# GD32VW553x register map
Vendor: GigaDevice; File version: 1.0
CPU: OTHER r0p0, little endian, no MPU, no FPU, 4 interrupt priority bits
Registers are 32-bit, read-write, reset 0x0 unless marked. A register's access mark holds for its fields unless they carry their own. Offsets are from the block's base; [hi:lo] are bit positions.

## USART0 — Universal synchronous/asynchronous receiver /transmitter
Base 0x40004800
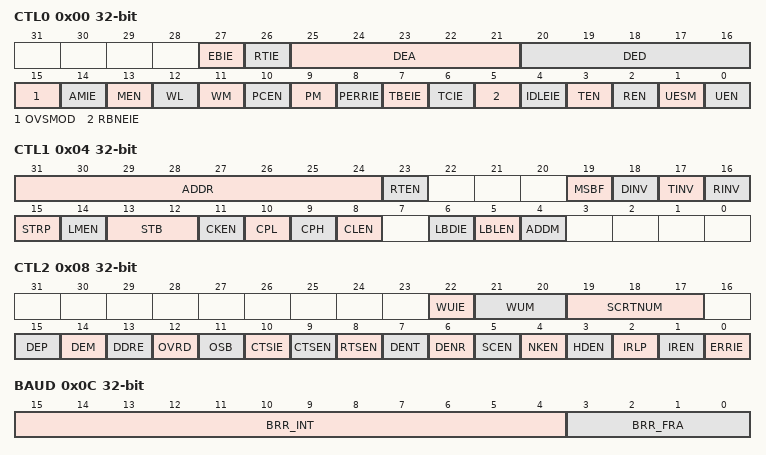
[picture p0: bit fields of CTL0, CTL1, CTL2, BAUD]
0x00 CTL0 — Control register 0
  [27] EBIE — End of Block interrupt enable
  [26] RTIE — Receiver timeout interrupt enable
  [25:21] DEA — Driver enable assertion time
  [20:16] DED — Driver enable de-assertion time
  [15] OVSMOD — Oversample mode
  [14] AMIE — ADDR match interrupt enable
  [13] MEN — Mute mode enable
  [12] WL — Word length
  [11] WM — Wakeup method in mute mode
  [10] PCEN — Parity control enable
  [9] PM — Parity mode
  [8] PERRIE — Parity error interrupt enable
  [7] TBEIE — Transmitter register empty interrupt enable
  [6] TCIE — Transmission complete interrupt enable
  [5] RBNEIE — Read data buffer not empty interrupt and overrun error interrupt enable
  [4] IDLEIE — IDLE line detected interrupt enable
  [3] TEN — Transmitter enable
  [2] REN — Receiver enable
  [1] UESM — USART enable in Deep-sleep mode
  [0] UEN — USART enable
0x04 CTL1 — Control register 1
  [31:24] ADDR — Address of the USART terminal
  [23] RTEN — Receiver timeout enable
  [19] MSBF — Most significant bit first
  [18] DINV — Data bit level inversion
  [17] TINV — TX pin level inversion
  [16] RINV — RX pin level inversion
  [15] STRP — Swap TX/RX pins
  [14] LMEN — LIN mode enable
  [13:12] STB — STOP bits length
  [11] CKEN — CK pin enable
  [10] CPL — Clock polarity
  [9] CPH — Clock phase
  [8] CLEN — CK length
  [6] LBDIE — LIN break detection interrupt enable
  [5] LBLEN — LIN break frame length
  [4] ADDM — Address detection mode
0x08 CTL2 — Control register 2
  [22] WUIE — Wakeup from deep-sleep mode interrupt enable
  [21:20] WUM — Wakeup mode from deep-sleep mode
  [19:17] SCRTNUM — Smartcard auto-retry number
  [15] DEP — Driver enable polarity mode
  [14] DEM — Driver enable mode
  [13] DDRE — Disable DMA on reception error
  [12] OVRD — Overrun disable
  [11] OSB — One sample bit method
  [10] CTSIE — CTS interrupt enable
  [9] CTSEN — CTS enable
  [8] RTSEN — RTS enable
  [7] DENT — DMA enable for transmission
  [6] DENR — DMA enable for reception
  [5] SCEN — Smartcard mode enable
  [4] NKEN — NACK enable in Smartcard mode
  [3] HDEN — Half-duplex enable
  [2] IRLP — IrDA low-power
  [1] IREN — IrDA mode enable
  [0] ERRIE — Error interrupt enable
0x0C BAUD — Baud rate generator register
  [15:4] BRR_INT — Integer of baud-rate divider
  [3:0] BRR_FRA — Fraction of baud-rate divider
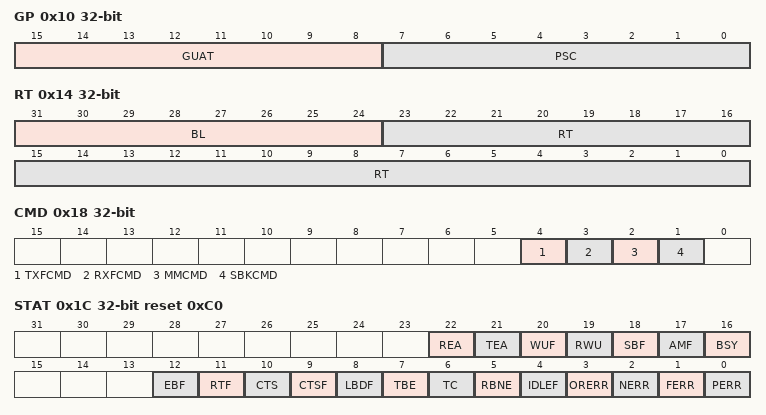
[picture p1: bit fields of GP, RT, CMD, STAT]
0x10 GP — Prescaler and guard time configuration register
  [15:8] GUAT — Guard time value in smartcard mode
  [7:0] PSC — Prescaler value for dividing the system clock
0x14 RT — Receiver timeout register
  [31:24] BL — Block Length
  [23:0] RT — Receiver timeout threshold
0x18 CMD — Command register
  [4] TXFCMD wo — Transmit data flush request
  [3] RXFCMD wo — Receive data flush command
  [2] MMCMD wo — Mute mode command
  [1] SBKCMD wo — Send break command
0x1C STAT reset 0xC0 — Status register
  [22] REA ro — Receive enable acknowledge flag
  [21] TEA ro — Transmit enable acknowledge flag
  [20] WUF ro — Wakeup from deep-sleep mode flag
  [19] RWU ro — Receiver wakeup from mute mode
  [18] SBF ro — Send break flag
  [17] AMF ro — ADDR match flag
  [16] BSY ro — Busy flag
  [12] EBF ro — End of block flag
  [11] RTF ro — Receiver timeout flag
  [10] CTS ro — CTS level
  [9] CTSF ro — CTS change flag
  [8] LBDF ro — LIN break detected flag
  [7] TBE ro — Transmit data register empty
  [6] TC ro — Transmission completed
  [5] RBNE ro — Read data buffer not empty
  [4] IDLEF ro — IDLE line detected flag
  [3] ORERR ro — Overrun error
  [2] NERR ro — Noise error flag
  [1] FERR ro — Frame error flag
  [0] PERR ro — Parity error flag
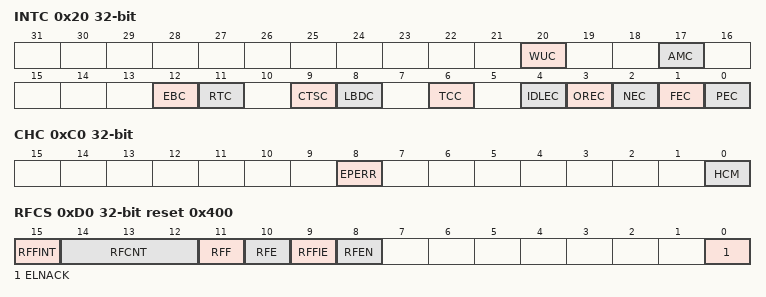
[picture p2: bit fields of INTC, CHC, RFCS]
0x20 INTC — Interrupt status clear register
  [20] WUC wo — Wakeup from deep-sleep mode clear
  [17] AMC wo — ADDR match clear
  [12] EBC wo — End of block clear
  [11] RTC wo — Receiver timeout clear
  [9] CTSC wo — CTS change clear
  [8] LBDC wo — LIN break detected clear
  [6] TCC wo — Transmission complete clear
  [4] IDLEC wo — Idle line detected clear
  [3] OREC wo — Overrun error clear
  [2] NEC wo — Noise detected clear
  [1] FEC wo — Frame error flag clear
  [0] PEC wo — Parity error clear
0x24 RDATA — Receive data register
  [8:0] RDATA ro — Receive data value
0x28 TDATA — Transmit data register
  [8:0] TDATA ro — Transmit data value
0xC0 CHC — USART coherence control register
  [8] EPERR — Early parity error flag
  [0] HCM — Hardware flow control coherence mode
0xD0 RFCS reset 0x400 — USART receive FIFO control and status register
  [15] RFFINT — Receive FIFO full interrupt flag
  [14:12] RFCNT — Receive FIFO counter number
  [11] RFF ro — Receive FIFO full flag
  [10] RFE ro — Receive FIFO empty flag
  [9] RFFIE — Receive FIFO full interrupt enable
  [8] RFEN — Receive FIFO enable
  [0] ELNACK — Early NACK when smartcard mode is selected
